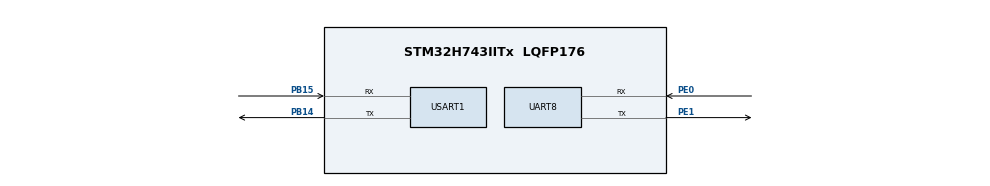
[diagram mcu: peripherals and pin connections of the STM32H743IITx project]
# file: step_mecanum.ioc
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CORTEX_M7.MPU_Control=__NULL
CORTEX_M7.default_mode_Activation=1
Dma.Request0=UART8_RX
Dma.UART8_RX.0.Direction=DMA_PERIPH_TO_MEMORY
Dma.UART8_RX.0.EventEnable=DISABLE
Dma.UART8_RX.0.FIFOMode=DMA_FIFOMODE_DISABLE
Dma.UART8_RX.0.Instance=DMA1_Stream1
Dma.UART8_RX.0.MemDataAlignment=DMA_MDATAALIGN_BYTE
Dma.UART8_RX.0.MemInc=DMA_MINC_ENABLE
Dma.UART8_RX.0.Mode=DMA_NORMAL
Dma.UART8_RX.0.PeriphDataAlignment=DMA_PDATAALIGN_BYTE
Dma.UART8_RX.0.PeriphInc=DMA_PINC_DISABLE
Dma.UART8_RX.0.Polarity=HAL_DMAMUX_REQ_GEN_RISING
Dma.UART8_RX.0.Priority=DMA_PRIORITY_LOW
Dma.UART8_RX.0.RequestNumber=1
Dma.UART8_RX.0.SignalID=NONE
Dma.UART8_RX.0.SyncEnable=DISABLE
Dma.UART8_RX.0.SyncPolarity=HAL_DMAMUX_SYNC_NO_EVENT
Dma.UART8_RX.0.SyncRequestNumber=1
Dma.UART8_RX.0.SyncSignalID=NONE
FREERTOS.INCLUDE_vTaskDelayUntil=1
FREERTOS.Tasks01=defaultTask,0,128,StartDefaultTask,Default,NULL,Dynamic,NULL,NULL
FREERTOS.configENABLE_FPU=1
Mcu.Family=STM32H7
Mcu.Name=STM32H743IITx
Mcu.Package=LQFP176
NVIC.DMA1_Stream1_IRQn=true\:5\:0\:false\:false\:true\:true\:false\:true\:true
NVIC.PriorityGroup=NVIC_PRIORITYGROUP_4
NVIC.TIM17_IRQn=true\:15\:0\:false\:false\:true\:false\:false\:true\:true
NVIC.TimeBase=TIM17_IRQn
NVIC.TimeBaseIP=TIM17
NVIC.UART8_IRQn=true\:5\:0\:false\:false\:true\:true\:true\:true\:true
PA13\ (JTMS/SWDIO).Mode=Serial_Wire
PA13\ (JTMS/SWDIO).Signal=DEBUG_JTMS-SWDIO
PA14\ (JTCK/SWCLK).Mode=Serial_Wire
PA14\ (JTCK/SWCLK).Signal=DEBUG_JTCK-SWCLK
PB14.Mode=Asynchronous
PB14.Signal=USART1_TX
PB15.Mode=Asynchronous
PB15.Signal=USART1_RX
PE0.Mode=Asynchronous
PE0.Signal=UART8_RX
PE1.Mode=Asynchronous
PE1.Signal=UART8_TX
PH0-OSC_IN\ (PH0).Mode=HSE-External-Oscillator
PH0-OSC_IN\ (PH0).Signal=RCC_OSC_IN
PH1-OSC_OUT\ (PH1).Mode=HSE-External-Oscillator
PH1-OSC_OUT\ (PH1).Signal=RCC_OSC_OUT
ProjectManager.HeapSize=0x200
ProjectManager.StackSize=0x400
ProjectManager.TargetToolchain=MDK-ARM V5.32
RCC.ADCFreq_Value=48375000
RCC.APB1Freq_Value=120000000
RCC.APB2Freq_Value=120000000
RCC.APB3Freq_Value=120000000
RCC.APB4Freq_Value=120000000
RCC.CortexFreq_Value=480000000
RCC.D1PPRE=RCC_APB3_DIV2
RCC.D2PPRE1=RCC_APB1_DIV2
RCC.D2PPRE2=RCC_APB2_DIV2
RCC.D3PPRE=RCC_APB4_DIV2
RCC.DIVM1=2
RCC.DIVN1=80
RCC.HCLKFreq_Value=240000000
RCC.HPRE=RCC_HCLK_DIV2
RCC.HSE_VALUE=24000000
RCC.PLLFRACN=0
RCC.PLLSourceVirtual=RCC_PLLSOURCE_HSE
RCC.SYSCLKFreq_VALUE=480000000
RCC.SYSCLKSource=RCC_SYSCLKSOURCE_PLLCLK
RCC.USBFreq_Value=480000000
USART1.VirtualMode-Asynchronous=VM_ASYNC
VP_FREERTOS_VS_CMSIS_V1.Mode=CMSIS_V1
VP_MEMORYMAP_VS_MEMORYMAP.Mode=CurAppReg
VP_SYS_VS_tim17.Mode=TIM17
board=custom

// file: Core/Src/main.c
/* USER CODE BEGIN Header */
/**
 ******************************************************************************
 * @file           : main.c
 * @brief          : Main program body
 ******************************************************************************
 * @attention
 *
 * Copyright (c) 2025 STMicroelectronics.
 * All rights reserved.
 *
 * This software is licensed under terms that can be found in the LICENSE file
 * in the root directory of this software component.
 * If no LICENSE file comes with this software, it is provided AS-IS.
 *
 ******************************************************************************
 */
/* USER CODE END Header */
#include "main.h"
#include "cmsis_os.h"
#include "dma.h"
#include "memorymap.h"
#include "usart.h"
#include "gpio.h"

/* USER CODE BEGIN PTD */
#include "maincpp.h"
/* USER CODE END PTD */

void SystemClock_Config(void);
void MX_FREERTOS_Init(void);

int main(void)
{

  /* MCU Configuration--------------------------------------------------------*/

  /* Reset of all peripherals, Initializes the Flash interface and the Systick. */
  HAL_Init();

  /* Configure the system clock */
  SystemClock_Config();

  /* Initialize all configured peripherals */
  MX_GPIO_Init();
  MX_DMA_Init();
  MX_USART1_UART_Init();
  MX_UART8_Init();
  /* USER CODE BEGIN 2 */
  main_cpp(); // 直接调用主函数
  /* USER CODE END 2 */

  /* Call init function for freertos objects (in cmsis_os2.c) */
  MX_FREERTOS_Init();

  /* Start scheduler */
  osKernelStart();

  /* We should never get here as control is now taken by the scheduler */

  /* Infinite loop */
  while (1)
  {

  }
}

void SystemClock_Config(void)
{
  RCC_OscInitTypeDef RCC_OscInitStruct = {0};
  RCC_ClkInitTypeDef RCC_ClkInitStruct = {0};

  /** Supply configuration update enable
  */
  HAL_PWREx_ConfigSupply(PWR_LDO_SUPPLY);

  /** Configure the main internal regulator output voltage
  */
  __HAL_PWR_VOLTAGESCALING_CONFIG(PWR_REGULATOR_VOLTAGE_SCALE0);

  while(!__HAL_PWR_GET_FLAG(PWR_FLAG_VOSRDY)) {}

  /** Initializes the RCC Oscillators according to the specified parameters
  * in the RCC_OscInitTypeDef structure.
  */
  RCC_OscInitStruct.OscillatorType = RCC_OSCILLATORTYPE_HSE;
  RCC_OscInitStruct.HSEState = RCC_HSE_ON;
  RCC_OscInitStruct.PLL.PLLState = RCC_PLL_ON;
  RCC_OscInitStruct.PLL.PLLSource = RCC_PLLSOURCE_HSE;
  RCC_OscInitStruct.PLL.PLLM = 2;
  RCC_OscInitStruct.PLL.PLLN = 80;
  RCC_OscInitStruct.PLL.PLLP = 2;
  RCC_OscInitStruct.PLL.PLLQ = 2;
  RCC_OscInitStruct.PLL.PLLR = 2;
  RCC_OscInitStruct.PLL.PLLRGE = RCC_PLL1VCIRANGE_3;
  RCC_OscInitStruct.PLL.PLLVCOSEL = RCC_PLL1VCOWIDE;
  RCC_OscInitStruct.PLL.PLLFRACN = 0;
  if (HAL_RCC_OscConfig(&RCC_OscInitStruct) != HAL_OK)
  {
    Error_Handler();
  }

  /** Initializes the CPU, AHB and APB buses clocks
  */
  RCC_ClkInitStruct.ClockType = RCC_CLOCKTYPE_HCLK|RCC_CLOCKTYPE_SYSCLK
                              |RCC_CLOCKTYPE_PCLK1|RCC_CLOCKTYPE_PCLK2
                              |RCC_CLOCKTYPE_D3PCLK1|RCC_CLOCKTYPE_D1PCLK1;
  RCC_ClkInitStruct.SYSCLKSource = RCC_SYSCLKSOURCE_PLLCLK;
  RCC_ClkInitStruct.SYSCLKDivider = RCC_SYSCLK_DIV1;
  RCC_ClkInitStruct.AHBCLKDivider = RCC_HCLK_DIV2;
  RCC_ClkInitStruct.APB3CLKDivider = RCC_APB3_DIV2;
  RCC_ClkInitStruct.APB1CLKDivider = RCC_APB1_DIV2;
  RCC_ClkInitStruct.APB2CLKDivider = RCC_APB2_DIV2;
  RCC_ClkInitStruct.APB4CLKDivider = RCC_APB4_DIV2;

  if (HAL_RCC_ClockConfig(&RCC_ClkInitStruct, FLASH_LATENCY_4) != HAL_OK)
  {
    Error_Handler();
  }
}

void HAL_TIM_PeriodElapsedCallback(TIM_HandleTypeDef *htim)
{
  if (htim->Instance == TIM17)
  {
    HAL_IncTick();
  }
}

void Error_Handler(void)
{
  __disable_irq();
  while (1)
  {
  }
}
